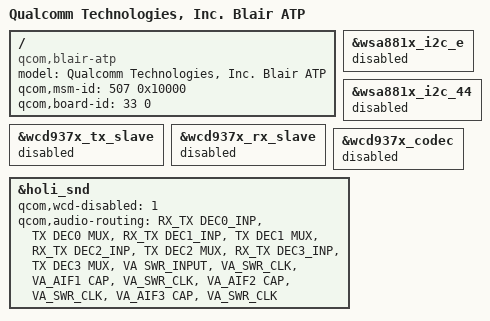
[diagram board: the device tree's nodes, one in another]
/dts-v1/;
/plugin/;

#include "blair-atp.dtsi"

/ {
	model = "Qualcomm Technologies, Inc. Blair ATP";
	compatible = "qcom,blair-atp", "qcom,blair", "qcom,atp";
	qcom,msm-id = <507 0x10000>;
	qcom,board-id = <33 0>;
};

&wsa881x_i2c_e {
	status = "disabled";
};

&wsa881x_i2c_44 {
	status = "disabled";
};

&wcd937x_tx_slave {
	status = "disabled";
};

&wcd937x_rx_slave {
	status = "disabled";
};

&wcd937x_codec {
	status = "disabled";
};

&holi_snd {
	qcom,wcd-disabled = <1>;
	qcom,audio-routing =
		"RX_TX DEC0_INP", "TX DEC0 MUX",
		"RX_TX DEC1_INP", "TX DEC1 MUX",
		"RX_TX DEC2_INP", "TX DEC2 MUX",
		"RX_TX DEC3_INP", "TX DEC3 MUX",
		"VA SWR_INPUT", "VA_SWR_CLK",
		"VA_AIF1 CAP", "VA_SWR_CLK",
		"VA_AIF2 CAP", "VA_SWR_CLK",
		"VA_AIF3 CAP", "VA_SWR_CLK";
};
